# nrf7120_enga_application register map
Vendor: Nordic Semiconductor; Series: nrf71; File version: 1
CPU: CM33 r0p4, little endian, MPU, FPU, 3 interrupt priority bits, 270 interrupts, 4 SAU regions
Registers are 32-bit, read-write, reset 0x0 unless marked. A register's access mark holds for its fields unless they carry their own. Offsets are from the block's base; [hi:lo] are bit positions; lines under a group give offsets from that group; {n}, {i} and the like mark numbered series.

## GLOBAL_WICR_NS — Wi-Fi Information Configuration Registers
Base 0x003FD000
{0x100+8i} MAC[{i}] (i=0..1) group — Unspecified
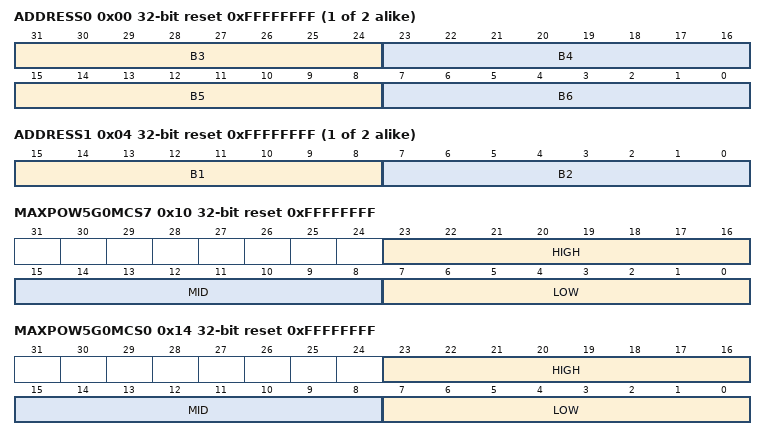
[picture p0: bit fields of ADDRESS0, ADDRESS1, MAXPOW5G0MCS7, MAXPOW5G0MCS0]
  0x00 ADDRESS0 ro reset 0xFFFFFFFF — Description cluster: MAC address for VIFn
    [31:24] B3 — 3rd byte (B3) of MAC address
    [23:16] B4 — 4th byte (B4) of MAC address
    [15:8] B5 — 5th byte (B5) of MAC address
    [7:0] B6 — 6th byte (B6) of MAC address
  0x04 ADDRESS1 ro reset 0xFFFFFFFF — Description cluster: MAC address for VIFn
    [15:8] B1 — 1st byte (B1) of MAC address
    [7:0] B2 — 2nd byte (B2) of MAC address
0x200 CALIB group — Unspecified
  0x00 XO reset 0xFFFFFFFF — XO adjustment
    [6:0] XO
  0x10 MAXPOW5G0MCS7 reset 0xFFFFFFFF — Max output power for MCS7
    [23:16] HIGH — Max output power for MCS7 in high 5GHz sub-band (channels 136 - 177)
    [15:8] MID — Max output power for MCS7 in mid 5GHz sub-band (channels 100 - 132)
    [7:0] LOW — Max output power for MCS7 in low 5GHz sub-band (channels 36 - 64)
  0x14 MAXPOW5G0MCS0 reset 0xFFFFFFFF — Max output power for MCS0
    [23:16] HIGH — Max output power for MCS0 in high 5GHz sub-band (channels 136 - 177)
    [15:8] MID — Max output power for MCS0 in mid 5GHz sub-band (channels 100 - 132)
    [7:0] LOW — Max output power for MCS0 in low 5GHz sub-band (channels 36 - 64)

## GLOBAL_FICR_NS — Factory Information Configuration Registers
Base 0x00FFC000
0x300 INFO group — Device info
  0x00 CONFIGID ro reset 0xFFFFFFFF — Configuration identifier
    [15:0] HWID — Identification number for the HW
  {0x4+4j} DEVICEID[{j}] (j=0..1) ro reset 0xFFFFFFFF — Description collection: Device identifier
    [31:0] DEVICEID — 64 bit unique device identifier
  {0xC+4j} UUID[{j}] (j=0..3) reset 0xFFFFFFFF — Description collection: 128-bit Universally Unique IDentifier (UUID).
    [31:0] UUID — Device UUID [n].
  0x1C PART ro reset 0xFFFFFFFF — Part code
    [31:0] PART
      0xFFFFFFFF=Unspecified
  0x20 VARIANT ro reset 0xFFFFFFFF — Part Variant, Hardware version and Production configuration
    [31:0] VARIANT — Part Variant, Hardware version and Production configuration, encoded as ASCII
      0xFFFFFFFF=Unspecified
  0x24 PACKAGE ro reset 0xFFFFFFFF — Package option
    [31:0] PACKAGE
      0xFFFFFFFF=Unspecified
  0x28 RAM ro reset 0xFFFFFFFF — RAM size (KB)
    [31:0] RAM
      0xFFFFFFFF=Unspecified
  0x30 MRAM ro reset 0xFFFFFFFF — MRAM size (KB)
    [31:0] MRAM
      0x5F4=K3072 (4088 KByte MRAM); 0xFFFFFFFF=Unspecified
{0x380+4i} ER[{i}] (i=0..3) ro reset 0xFFFFFFFF — Description collection: Common encryption root key, word n
  [31:0] ER — Encryption Root, word n
{0x390+4i} IR[{i}] (i=0..3) ro reset 0xFFFFFFFF — Description collection: Common identity root key, word n
  [31:0] IR — Identity Root, word n
0x3A0 DEVICEADDRTYPE ro reset 0xFFFFFFFF — Device address type
  [0] DEVICEADDRTYPE
    0=Public address; 1=Random address
{0x3A4+4i} DEVICEADDR[{i}] (i=0..1) ro reset 0xFFFFFFFF — Description collection: Device address n
  [31:0] DEVICEADDR — 48 bit device address
{0x400+8i} TRIMCNF[{i}] (i=0..63) group — Unspecified
  0x00 ADDR ro reset 0xFFFFFFFF — Description cluster: Address of the register which will be written
    [31:0] Address
  0x04 DATA ro reset 0xFFFFFFFF — Description cluster: Data to be written into the register
0x600 NFC group — Unspecified
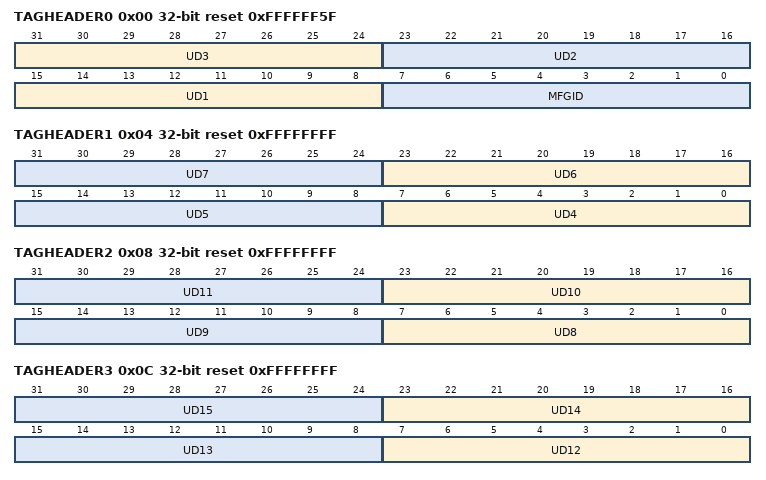
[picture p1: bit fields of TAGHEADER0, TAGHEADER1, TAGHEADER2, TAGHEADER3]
  0x00 TAGHEADER0 ro reset 0xFFFFFF5F — Default header for NFC Tag. Software can read these values to populate NFCID1_3RD_LAST, NFCID1_2ND_LAST and NFCID1_LAST.
    [31:24] UD3 — Unique identifier byte 3
    [23:16] UD2 — Unique identifier byte 2
    [15:8] UD1 — Unique identifier byte 1
    [7:0] MFGID — Default Manufacturer ID: Nordic Semiconductor ASA has ICM 0x5F
  0x04 TAGHEADER1 ro reset 0xFFFFFFFF — Default header for NFC Tag. Software can read these values to populate NFCID1_3RD_LAST, NFCID1_2ND_LAST and NFCID1_LAST.
    [8n-25:8n-32] UD{n} (n=4..7) — Unique identifier byte {n}
  0x08 TAGHEADER2 ro reset 0xFFFFFFFF — Default header for NFC Tag. Software can read these values to populate NFCID1_3RD_LAST, NFCID1_2ND_LAST and NFCID1_LAST.
    [8n-57:8n-64] UD{n} (n=8..11) — Unique identifier byte {n}
  0x0C TAGHEADER3 ro reset 0xFFFFFFFF — Default header for NFC Tag. Software can read these values to populate NFCID1_3RD_LAST, NFCID1_2ND_LAST and NFCID1_LAST.
    [8n-89:8n-96] UD{n} (n=12..15) — Unique identifier byte {n}

## Notices in the file
Copyright (c) 2010 - 2025, Nordic Semiconductor ASA All rights reserved.
SPDX-License-Identifier: BSD-3-Clause
Redistribution and use in source and binary forms, with or without
modification, are permitted provided that the following conditions are met:
1. Redistributions of source code must retain the above copyright notice, this
list of conditions and the following disclaimer.
2. Redistributions in binary form must reproduce the above copyright
notice, this list of conditions and the following disclaimer in the
documentation and/or other materials provided with the distribution.
3. Neither the name of Nordic Semiconductor ASA nor the names of its
contributors may be used to endorse or promote products derived from this
software without specific prior written permission.
THIS SOFTWARE IS PROVIDED BY THE COPYRIGHT HOLDERS AND CONTRIBUTORS "AS IS"
AND ANY EXPRESS OR IMPLIED WARRANTIES, INCLUDING, BUT NOT LIMITED TO, THE
IMPLIED WARRANTIES OF MERCHANTABILITY, AND FITNESS FOR A PARTICULAR PURPOSE
ARE DISCLAIMED. IN NO EVENT SHALL NORDIC SEMICONDUCTOR ASA OR CONTRIBUTORS BE
LIABLE FOR ANY DIRECT, INDIRECT, INCIDENTAL, SPECIAL, EXEMPLARY, OR
CONSEQUENTIAL DAMAGES (INCLUDING, BUT NOT LIMITED TO, PROCUREMENT OF
SUBSTITUTE GOODS OR SERVICES; LOSS OF USE, DATA, OR PROFITS; OR BUSINESS
INTERRUPTION) HOWEVER CAUSED AND ON ANY THEORY OF LIABILITY, WHETHER IN
CONTRACT, STRICT LIABILITY, OR TORT (INCLUDING NEGLIGENCE OR OTHERWISE)
ARISING IN ANY WAY OUT OF THE USE OF THIS SOFTWARE, EVEN IF ADVISED OF THE
POSSIBILITY OF SUCH DAMAGE.
